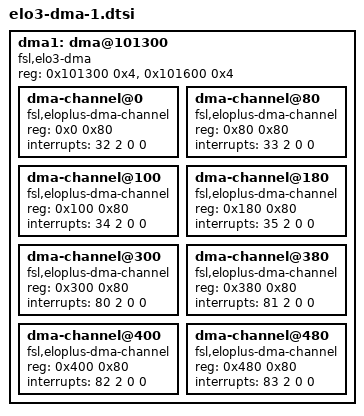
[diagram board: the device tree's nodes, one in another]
// SPDX-License-Identifier: GPL-2.0-or-later
/*
 * QorIQ Elo3 DMA device tree stub [ controller @ offset 0x101000 ]
 *
 * Copyright 2013 Freescale Semiconductor Inc.
 */

dma1: dma@101300 {
	#address-cells = <1>;
	#size-cells = <1>;
	compatible = "fsl,elo3-dma";
	reg = <0x101300 0x4>,
	      <0x101600 0x4>;
	ranges = <0x0 0x101100 0x500>;
	dma-channel@0 {
		compatible = "fsl,eloplus-dma-channel";
		reg = <0x0 0x80>;
		interrupts = <32 2 0 0>;
	};
	dma-channel@80 {
		compatible = "fsl,eloplus-dma-channel";
		reg = <0x80 0x80>;
		interrupts = <33 2 0 0>;
	};
	dma-channel@100 {
		compatible = "fsl,eloplus-dma-channel";
		reg = <0x100 0x80>;
		interrupts = <34 2 0 0>;
	};
	dma-channel@180 {
		compatible = "fsl,eloplus-dma-channel";
		reg = <0x180 0x80>;
		interrupts = <35 2 0 0>;
	};
	dma-channel@300 {
		compatible = "fsl,eloplus-dma-channel";
		reg = <0x300 0x80>;
		interrupts = <80 2 0 0>;
	};
	dma-channel@380 {
		compatible = "fsl,eloplus-dma-channel";
		reg = <0x380 0x80>;
		interrupts = <81 2 0 0>;
	};
	dma-channel@400 {
		compatible = "fsl,eloplus-dma-channel";
		reg = <0x400 0x80>;
		interrupts = <82 2 0 0>;
	};
	dma-channel@480 {
		compatible = "fsl,eloplus-dma-channel";
		reg = <0x480 0x80>;
		interrupts = <83 2 0 0>;
	};
};
